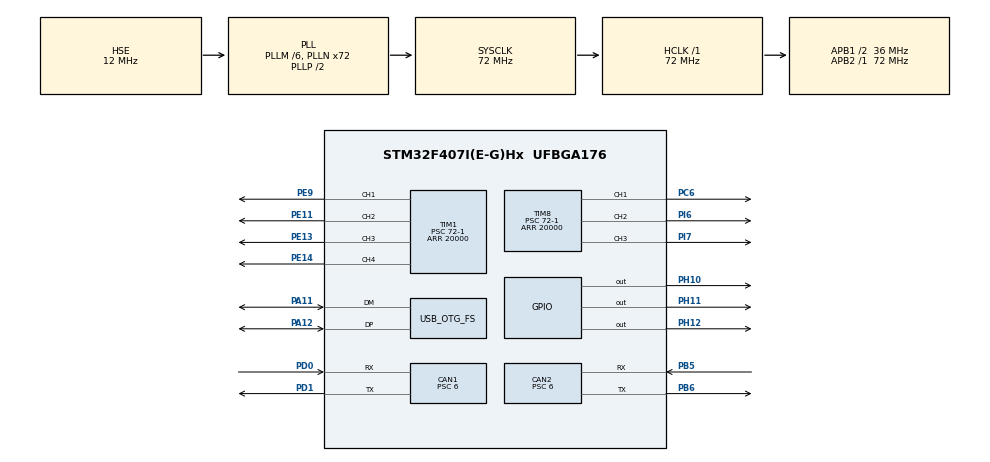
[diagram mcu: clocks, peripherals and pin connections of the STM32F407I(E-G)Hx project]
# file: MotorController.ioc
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CAN1.ABOM=ENABLE
CAN1.BS1=CAN_BS1_2TQ
CAN1.BS2=CAN_BS2_3TQ
CAN1.CalculateTimeQuantum=166.66666666666669
CAN1.Prescaler=6
CAN2.ABOM=ENABLE
CAN2.BS1=CAN_BS1_2TQ
CAN2.BS2=CAN_BS2_3TQ
CAN2.CalculateTimeQuantum=166.66666666666669
CAN2.Prescaler=6
Mcu.Family=STM32F4
Mcu.Name=STM32F407I(E-G)Hx
Mcu.Package=UFBGA176
NVIC.CAN1_RX0_IRQn=true\:1\:0\:true\:false\:true\:true\:true
NVIC.CAN1_TX_IRQn=true\:1\:0\:true\:false\:true\:true\:true
NVIC.CAN2_RX0_IRQn=true\:1\:0\:true\:false\:true\:true\:true
NVIC.CAN2_TX_IRQn=true\:1\:0\:true\:false\:true\:true\:true
NVIC.OTG_FS_IRQn=true\:1\:0\:true\:false\:true\:true\:true
NVIC.PriorityGroup=NVIC_PRIORITYGROUP_4
PA11.Mode=Device_Only
PA11.Signal=USB_OTG_FS_DM
PA12.Mode=Device_Only
PA12.Signal=USB_OTG_FS_DP
PA13.Mode=Serial_Wire
PA13.Signal=SYS_JTMS-SWDIO
PA14.Mode=Serial_Wire
PA14.Signal=SYS_JTCK-SWCLK
PB5.Mode=Slave
PB5.Signal=CAN2_RX
PB6.Mode=Slave
PB6.Signal=CAN2_TX
PC6.Signal=S_TIM8_CH1
PD0.Mode=Master
PD0.Signal=CAN1_RX
PD1.Mode=Master
PD1.Signal=CAN1_TX
PE11.Signal=S_TIM1_CH2
PE13.Signal=S_TIM1_CH3
PE14.Signal=S_TIM1_CH4
PE9.Signal=S_TIM1_CH1
PH0-OSC_IN.Mode=HSE-External-Oscillator
PH0-OSC_IN.Signal=RCC_OSC_IN
PH1-OSC_OUT.Mode=HSE-External-Oscillator
PH1-OSC_OUT.Signal=RCC_OSC_OUT
PH10.Signal=GPIO_Output
PH11.Signal=GPIO_Output
PH12.Signal=GPIO_Output
PI6.Signal=S_TIM8_CH2
PI7.Signal=S_TIM8_CH3
ProjectManager.HeapSize=0x1000
ProjectManager.StackSize=0x400
ProjectManager.TargetToolchain=MDK-ARM V5.27
RCC.48MHZClocksFreq_Value=48000000
RCC.AHBFreq_Value=72000000
RCC.APB1CLKDivider=RCC_HCLK_DIV2
RCC.APB1Freq_Value=36000000
RCC.APB1TimFreq_Value=72000000
RCC.APB2Freq_Value=72000000
RCC.APB2TimFreq_Value=72000000
RCC.CortexFreq_Value=72000000
RCC.HCLKFreq_Value=72000000
RCC.HSE_VALUE=12000000
RCC.HSI_VALUE=16000000
RCC.LSE_VALUE=32768
RCC.PLLM=6
RCC.PLLN=72
RCC.PLLQ=3
RCC.SYSCLKFreq_VALUE=72000000
RCC.SYSCLKSource=RCC_SYSCLKSOURCE_PLLCLK
RCC.VCOOutputFreq_Value=144000000
SH.S_TIM1_CH1.0=TIM1_CH1,PWM Generation1 CH1
SH.S_TIM1_CH2.0=TIM1_CH2,PWM Generation2 CH2
SH.S_TIM1_CH3.0=TIM1_CH3,PWM Generation3 CH3
SH.S_TIM1_CH4.0=TIM1_CH4,PWM Generation4 CH4
SH.S_TIM8_CH1.0=TIM8_CH1,PWM Generation1 CH1
SH.S_TIM8_CH2.0=TIM8_CH2,PWM Generation2 CH2
SH.S_TIM8_CH3.0=TIM8_CH3,PWM Generation3 CH3
TIM1.AutoReloadPreload=TIM_AUTORELOAD_PRELOAD_ENABLE
TIM1.Channel-PWM\ Generation1\ CH1=TIM_CHANNEL_1
TIM1.Channel-PWM\ Generation2\ CH2=TIM_CHANNEL_2
TIM1.Channel-PWM\ Generation3\ CH3=TIM_CHANNEL_3
TIM1.Channel-PWM\ Generation4\ CH4=TIM_CHANNEL_4
TIM1.Period=20000
TIM1.Prescaler=72-1
TIM8.AutoReloadPreload=TIM_AUTORELOAD_PRELOAD_ENABLE
TIM8.Channel-PWM\ Generation1\ CH1=TIM_CHANNEL_1
TIM8.Channel-PWM\ Generation2\ CH2=TIM_CHANNEL_2
TIM8.Channel-PWM\ Generation3\ CH3=TIM_CHANNEL_3
TIM8.Period=20000
TIM8.Prescaler=72-1
USB_DEVICE.CLASS_NAME_FS=CDC
USB_DEVICE.VirtualMode-CDC_FS=Cdc
USB_DEVICE.VirtualModeFS=Cdc_FS
USB_OTG_FS.VirtualMode=Device_Only
VP_TIM1_VS_ClockSourceINT.Mode=Internal
VP_TIM8_VS_ClockSourceINT.Mode=Internal
VP_USB_DEVICE_VS_USB_DEVICE_CDC_FS.Mode=CDC_FS
board=custom

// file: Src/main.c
/* USER CODE BEGIN Header */
/**
  ******************************************************************************
  * @file           : main.c
  * @brief          : Main program body
  ******************************************************************************
  * @attention
  *
  * <h2><center>&copy; Copyright (c) 2021 STMicroelectronics.
  * All rights reserved.</center></h2>
  *
  * This software component is licensed by ST under Ultimate Liberty license
  * SLA0044, the "License"; You may not use this file except in compliance with
  * the License. You may obtain a copy of the License at:
  *                             www.st.com/SLA0044
  *
  ******************************************************************************
  */
/* USER CODE END Header */

#include "main.h"
#include "can.h"
#include "tim.h"
#include "usb_device.h"
#include "gpio.h"

/* USER CODE BEGIN Includes */
#include "USER_CAN.h"
#include "MotorCtrl.h"
#include "Led.h"
/* USER CODE END Includes */

void SystemClock_Config(void);

int main(void)
{

  /* MCU Configuration--------------------------------------------------------*/

  /* Reset of all peripherals, Initializes the Flash interface and the Systick. */
  HAL_Init();

  /* Configure the system clock */
  SystemClock_Config();

  /* Initialize all configured peripherals */
  MX_GPIO_Init();
  MX_CAN1_Init();
  MX_CAN2_Init();
  MX_USB_DEVICE_Init();
  MX_TIM1_Init();
  MX_TIM8_Init();
  /* USER CODE BEGIN 2 */
	USER_CAN_Init();
  /* USER CODE END 2 */

  /* Infinite loop */
  /* USER CODE BEGIN WHILE */
  while (1)
  {
		MotorCtrl_Exec();
		Led_Exec();
		HAL_Delay(1);
    /* USER CODE END WHILE */

  }
}

void SystemClock_Config(void)
{
  RCC_OscInitTypeDef RCC_OscInitStruct = {0};
  RCC_ClkInitTypeDef RCC_ClkInitStruct = {0};

  /** Configure the main internal regulator output voltage
  */
  __HAL_RCC_PWR_CLK_ENABLE();
  __HAL_PWR_VOLTAGESCALING_CONFIG(PWR_REGULATOR_VOLTAGE_SCALE1);
  /** Initializes the CPU, AHB and APB busses clocks
  */
  RCC_OscInitStruct.OscillatorType = RCC_OSCILLATORTYPE_HSE;
  RCC_OscInitStruct.HSEState = RCC_HSE_ON;
  RCC_OscInitStruct.PLL.PLLState = RCC_PLL_ON;
  RCC_OscInitStruct.PLL.PLLSource = RCC_PLLSOURCE_HSE;
  RCC_OscInitStruct.PLL.PLLM = 6;
  RCC_OscInitStruct.PLL.PLLN = 72;
  RCC_OscInitStruct.PLL.PLLP = RCC_PLLP_DIV2;
  RCC_OscInitStruct.PLL.PLLQ = 3;
  if (HAL_RCC_OscConfig(&RCC_OscInitStruct) != HAL_OK)
  {
    Error_Handler();
  }
  /** Initializes the CPU, AHB and APB busses clocks
  */
  RCC_ClkInitStruct.ClockType = RCC_CLOCKTYPE_HCLK|RCC_CLOCKTYPE_SYSCLK
                              |RCC_CLOCKTYPE_PCLK1|RCC_CLOCKTYPE_PCLK2;
  RCC_ClkInitStruct.SYSCLKSource = RCC_SYSCLKSOURCE_PLLCLK;
  RCC_ClkInitStruct.AHBCLKDivider = RCC_SYSCLK_DIV1;
  RCC_ClkInitStruct.APB1CLKDivider = RCC_HCLK_DIV2;
  RCC_ClkInitStruct.APB2CLKDivider = RCC_HCLK_DIV1;

  if (HAL_RCC_ClockConfig(&RCC_ClkInitStruct, FLASH_LATENCY_2) != HAL_OK)
  {
    Error_Handler();
  }
}

void Error_Handler(void)
{
}

/************************ (C) COPYRIGHT STMicroelectronics *****END OF FILE****/
